VERSION ""

NS_ :

BS_:

BU_: Device Host

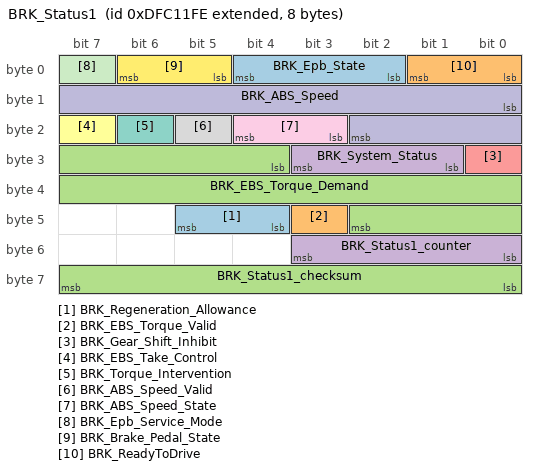
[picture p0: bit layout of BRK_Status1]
BO_ 2382107134 BRK_Status1: 8 Vector__XXX
 SG_ BRK_Regeneration_Allowance : 44|2@1+ (1,0) [0|3] "" Vector__XXX
 SG_ BRK_EBS_Torque_Valid : 43|1@1+ (1,0) [0|0] "" Vector__XXX
 SG_ BRK_EBS_Torque_Demand : 28|15@1+ (0.1,0) [0|3276.7] "N*m" Vector__XXX
 SG_ BRK_System_Status : 25|3@1+ (1,0) [0|7] "" Vector__XXX
 SG_ BRK_Gear_Shift_Inhibit : 24|1@1+ (1,0) [0|1] "" Vector__XXX
 SG_ BRK_EBS_Take_Control : 23|1@1+ (1,0) [0|1] "" Vector__XXX
 SG_ BRK_Torque_Intervention : 22|1@1+ (1,0) [0|1] "" Vector__XXX
 SG_ BRK_ABS_Speed_Valid : 21|1@1+ (1,0) [0|1] "" Vector__XXX
 SG_ BRK_ABS_Speed_State : 19|2@1+ (1,0) [0|3] "" Vector__XXX
 SG_ BRK_ABS_Speed : 8|11@1+ (0.125,0) [0|255] "kph" Vector__XXX
 SG_ BRK_Epb_Service_Mode : 7|1@1+ (1,0) [0|1] "" Vector__XXX
 SG_ BRK_Brake_Pedal_State : 5|2@1+ (1,0) [0|3] "" Vector__XXX
 SG_ BRK_Epb_State : 2|3@1+ (1,0) [0|7] "" Vector__XXX
 SG_ BRK_ReadyToDrive : 0|2@1+ (1,0) [0|3] "" Vector__XXX
 SG_ BRK_Status1_checksum : 56|8@1+ (1,0) [0|255] "" Vector__XXX
 SG_ BRK_Status1_counter : 48|4@1+ (1,0) [0|15] "" Vector__XXX

CM_ "Arrival Drivetrain Controller Database.
$DBC storage: //depot/auto/dbc/Software_Modules/Drivetrain_Controller/ArrivalDTC/ $
$Change: 0 $
$DateTime: 2020/11/02 14:30:00 $
$Revision: #1 $
$Author: lyamin@arrival.com $
";
CM_ BO_ 2382107134 "Message with general information about current Drivetrain System state";
CM_ SG_ 2382107134 BRK_EBS_Torque_Valid "Validity flag of EBS torque";
CM_ SG_ 2382107134 BRK_EBS_Torque_Demand "EBS Torque Demand";
CM_ SG_ 2382107134 BRK_System_Status "Braking system status";
CM_ SG_ 2382107134 BRK_Gear_Shift_Inhibit "Request of gear shift inhibition from the braking system";
CM_ SG_ 2382107134 BRK_EBS_Take_Control "Flag of breaking system that EBS take control of torque";
CM_ SG_ 2382107134 BRK_Torque_Intervention "Flag of torque intervention from braking system";
CM_ SG_ 2382107134 BRK_ABS_Speed_Valid "Validity of Abs speed";
CM_ SG_ 2382107134 BRK_Epb_Service_Mode "EPB is in service mode. ";
CM_ SG_ 2382107134 BRK_ReadyToDrive "Drivetrain readiness flag";
BA_DEF_  "BusType" STRING ;
BA_DEF_  "DBName" STRING ;
BA_DEF_  "DatabaseVersion" STRING ;
BA_DEF_ BO_  "GenMsgCycleTime" INT 0 3600000;
BA_DEF_ BO_  "GenMsgILSupport" ENUM  "No","Yes";
BA_DEF_ BO_  "GenMsgRequestable" INT 0 1;
BA_DEF_ BO_  "GenMsgSendType" ENUM  "cyclic","NotUsed","NotUsed","NotUsed","NotUsed","NotUsed","NotUsed","IfActive","noMsgSendType";
BA_DEF_ SG_  "GenSigEVName" STRING ;
BA_DEF_ SG_  "GenSigILSupport" ENUM  "No","Yes";
BA_DEF_ SG_  "GenSigSendType" ENUM  "Cyclic","OnWrite","OnWriteWithRepetition","OnChange","OnChangeWithRepetition","IfActive","IfActiveWithRepetition","NoSigSendType";
BA_DEF_ SG_  "GenSigStartValue" INT 0 2147483647;
BA_DEF_ BU_  "NmStationAddress" INT 0 255;
BA_DEF_  "ProtocolType" STRING ;
BA_DEF_  "SAE_J1939_21_SpecVersion" STRING ;
BA_DEF_  "SAE_J1939_71_SpecVersion" STRING ;
BA_DEF_  "SAE_J1939_73_SpecVersion" STRING ;
BA_DEF_  "SAE_J1939_75_SpecVersion" STRING ;
BA_DEF_  "SAE_J1939_81_SpecVersion" STRING ;
BA_DEF_  "SAE_J1939_DA_SpecVersion" STRING ;
BA_DEF_ BO_  "Producer" STRING ;
BA_DEF_ SG_  "SigType" ENUM  "Default","Range","RangeSigned","ASCII","Discrete","Control","ReferencePGN","DTC","StringDelimiter","StringLength","StringLengthControl","MessageCounter","MessageChecksum";
BA_DEF_ BO_  "VFrameFormat" ENUM  "StandardCAN","ExtendedCAN","reserved","J1939PG","reserved","reserved","reserved","reserved","reserved","reserved","reserved","reserved","reserved","reserved","StandardCAN_FD","ExtendedCAN_FD";
BA_DEF_DEF_  "BusType" "";
BA_DEF_DEF_ "Producer" "BRK" ;
BA_DEF_DEF_  "DBName" "";
BA_DEF_DEF_  "DatabaseVersion" "";
BA_DEF_DEF_  "GenMsgCycleTime" 0;
BA_DEF_DEF_  "GenMsgILSupport" "Yes";
BA_DEF_DEF_  "GenMsgRequestable" 1;
BA_DEF_DEF_  "GenMsgSendType" "noMsgSendType";
BA_DEF_DEF_  "GenSigEVName" "Env@Nodename_@Signame";
BA_DEF_DEF_  "GenSigILSupport" "Yes";
BA_DEF_DEF_  "GenSigSendType" "NoSigSendType";
BA_DEF_DEF_  "GenSigStartValue" 0;
BA_DEF_DEF_  "NmStationAddress" 254;
BA_DEF_DEF_  "ProtocolType" "";
BA_DEF_DEF_  "SAE_J1939_21_SpecVersion" "";
BA_DEF_DEF_  "SAE_J1939_71_SpecVersion" "";
BA_DEF_DEF_  "SAE_J1939_73_SpecVersion" "";
BA_DEF_DEF_  "SAE_J1939_75_SpecVersion" "";
BA_DEF_DEF_  "SAE_J1939_81_SpecVersion" "";
BA_DEF_DEF_  "SAE_J1939_DA_SpecVersion" "";
BA_DEF_DEF_  "SigType" "Default";
BA_DEF_DEF_  "VFrameFormat" "J1939PG";
BA_ "SAE_J1939_DA_SpecVersion" "2015-01";
BA_ "SAE_J1939_81_SpecVersion" "2012-05";
BA_ "SAE_J1939_75_SpecVersion" "2012-05";
BA_ "SAE_J1939_73_SpecVersion" "2012-10";
BA_ "SAE_J1939_71_SpecVersion" "2012-10";
BA_ "SAE_J1939_21_SpecVersion" "2006-10";
BA_ "ProtocolType" "J1939";
BA_ "DatabaseVersion" "1.0";
BA_ "BusType" "CAN";
BA_ "DBName" "BRK_Status1";
BA_ "GenMsgCycleTime" BO_ 2382107134 50;
BA_ "GenMsgSendType" BO_ 2382107134 0;
BA_ "SigType" SG_ 2382107134 BRK_Status1_checksum 12;
BA_ "GenSigSendType" SG_ 2382107134 BRK_Status1_checksum 0;
BA_ "GenSigSendType" SG_ 2382107134 BRK_Status1_counter 0;
BA_ "SigType" SG_ 2382107134 BRK_Status1_counter 11;
VAL_ 2382107134 BRK_Regeneration_Allowance 3 "NA" 2 "Error" 1 "Allowed" 0 "NotAllowed" ;
VAL_ 2382107134 BRK_System_Status 7 "NA" 6 "Reserved" 5 "Reserved" 4 "Reserved" 3 "MaxMod" 2 "AddlMod" 1 "DrvrBrkDmd" 0 "NoBrkDmd" ;
VAL_ 2382107134 BRK_ABS_Speed_State 3 "Reserved" 2 "Error" 1 "OK" 0 "NA" ;
VAL_ 2382107134 BRK_Brake_Pedal_State 3 "NA" 2 "Error" 1 "Pressed" 0 "NotPressed" ;
VAL_ 2382107134 BRK_Epb_State 7 "NA" 6 "Error" 5 "Reserved" 4 "Reserved" 3 "Unlocked" 2 "Locked" 1 "Unlocking" 0 "Locking" ;
VAL_ 2382107134 BRK_ReadyToDrive 3 "NA" 2 "RESERVED" 1 "READY" 0 "NOT_READY" ;
